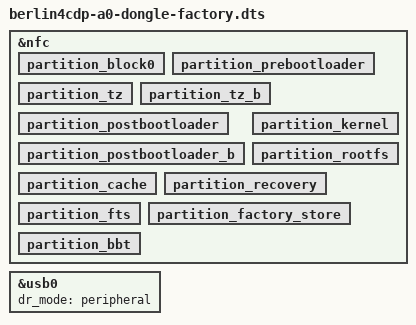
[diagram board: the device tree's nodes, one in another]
/*
 * MARVELL BERLIN4CDP Dongle board device tree source
 *
 * Author:	Hongjun Yuan <hyuan@marvell.com>
 * Copyright (c) 2015 Marvell Technology Group Ltd.
 *		http://www.marvell.com
 *
 * This program is free software; you can redistribute it and/or modify
 * it under the terms of the GNU General Public License version 2 as
 * published by the Free Software Foundation.
*/

/dts-v1/;

#include "berlin4cdp-dongle-memreserve.dtsi"
#include "berlin4cdp-a0-dongle-common.dtsi"
#include "berlin4cdp-dongle-memlayout.dtsi"

&nfc {
	partition_block0 {
		/delete-property/ read-only;
	};

	partition_prebootloader {
		/delete-property/ read-only;
	};

	partition_tz {
		/delete-property/ read-only;
	};

	partition_tz_b {
		/delete-property/ read-only;
	};

	partition_postbootloader {
		/delete-property/ read-only;
	};

	partition_postbootloader_b {
		/delete-property/ read-only;
	};

	partition_kernel {
		/delete-property/ read-only;
	};

	partition_rootfs {
		/delete-property/ read-only;
	};

	partition_cache {
		/delete-property/ read-only;
	};

	partition_recovery {
		/delete-property/ read-only;
	};

	partition_fts {
		/delete-property/ read-only;
	};

	partition_factory_store {
		/delete-property/ read-only;
	};

	partition_bbt {
		/delete-property/ read-only;
	};
};

&usb0 {
		dr_mode = "peripheral";
};
